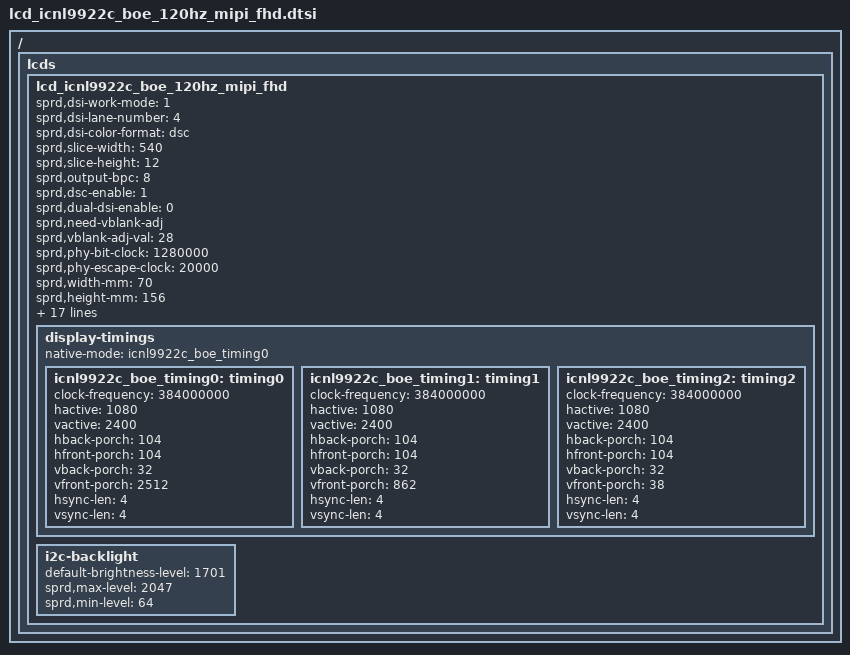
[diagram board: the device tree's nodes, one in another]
/ {
	fragment {
		target-path = "/";
		__overlay__ {
			lcds {
				lcd_icnl9922c_boe_120hz_mipi_fhd: lcd_icnl9922c_boe_120hz_mipi_fhd {

					sprd,dsi-work-mode = <1>; /* video burst mode*/
					sprd,dsi-lane-number = <4>;
					sprd,dsi-color-format = "dsc";
					sprd,slice-width = <540>;
					sprd,slice-height = <12>;
					sprd,output-bpc = <8>;
					sprd,dsc-enable = <1>;
					sprd,dual-dsi-enable = <0>;
					sprd,need-vblank-adj;
					sprd,vblank-adj-val = <28>;

					sprd,phy-bit-clock = <1280000>;
					sprd,phy-escape-clock = <20000>;/* kHz */
					sprd,width-mm = <70>;
					sprd,height-mm = <156>;
					sprd,vrr-enabled;
					sprd,esd-check-enable = <1>;
					sprd,esd-check-mode = <1>;
					sprd,esd-check-period = <2000>;
					/*sprd,esd-check-register = <0xA>;*/
					/*sprd,esd-check-value = <0x9c>;*/

					sprd,reset-on-sequence = <1 15>, <0 5>, <1 15>;
					sprd,reset-off-sequence = <1 10>;
					/*ontim,tp-reset-flag;*/
					sprd,need-execute-shutdown;
					ontim,qrcode-read-flag;
					sprd,qrcode-reg = <0x95 23>;
					sprd,qrcode-read-command = [
						39 00 00 04 F0 99 22 0C
						];

					sprd,initial-command = [
						39 00 00 04 F0 99 22 0C
						39 00 00 13 C1 00 00 20 26 26 04 68 68 04 60 19 22 50 01 12 07 5F FF
						39 00 00 06 C2 00 05 01 10 80
						39 00 00 0E B8 03 01 01 81 00 80 00 00 00 00 1F 00 20
						15 00 00 02 BA 01
						39 00 00 06 D0 0C 23 18 00 00
						39 00 00 03 35 00 00
						39 02 00 03 55 03 00
						39 00 00 03 51 07 FF
						39 00 00 14 E0 0C 00 B0 0C 00 15 7C 29 04 21 01 00 00 00 00 2E 17 0C 98
						39 00 00 20 E1 0F 1F 2F 3F 4F 5F 6F 7F 90 A0 B0 C0 D0 E0 E8 EC ED EF F1 F8 F8 F8 F9 FB FB FC FD FE FF FF FF
						39 00 00 21 E2 36 24 37 4B 38 72 39 99 3D 00 3C 0F 3B C2 3B A5 3C 28 3C ED 3D B1 3E 76 3F 3A 3F FF 3F FF 3F FF
						39 00 00 04 F0 00 00 00
						39 00 00 03 53 2C 00
						39 64 00 03 11 00 00
						39 0A 00 03 29 00 00
						39 01 00 03 AC 05 00
						];

					sprd,sleep-in-command = [
						39 00 00 04 F0 99 22 0C
						39 00 00 09 BB 01 02 03 0A 04 13 14 12
						39 00 00 04 F0 00 00 00
						39 00 00 03 AC 0A 00
						39 14 00 03 28 00 00
						39 78 00 03 10 00 00
						];
					sprd,sleep-out-command = [
						39 00 00 04 F0 99 22 0C
						39 00 00 13 C1 00 00 20 26 26 04 68 68 04 60 19 22 50 01 12 07 5F FF
						39 00 00 06 C2 00 05 01 10 80
						39 00 00 0E B8 03 01 01 81 00 80 00 00 00 00 1F 00 20
						15 00 00 02 BA 01
						39 00 00 06 D0 0C 23 18 00 00
						39 00 00 14 E0 0C 00 B0 0C 00 15 7C 29 04 81 1F 00 00 00 00 2E 17 0C 98
						39 00 00 20 E1 0F 1F 2F 3F 4F 5F 6F 7F 90 A0 B0 C0 D0 E0 E8 EC ED EF F1 F8 F8 F8 F9 FB FB FC FD FE FF FF FF
						39 00 00 21 E2 36 24 37 4B 38 72 39 99 3D 00 3C 0F 3B C2 3B A5 3C 28 3C ED 3D B1 3E 76 3F 3A 3F FF 3F FF 3F FF
						39 00 00 04 F0 00 00 00
						39 00 00 03 35 00 00
						39 02 00 03 55 03 00
						39 00 00 03 51 07 FF
						39 00 00 03 53 2C 00
						39 64 00 03 11 00 00
						39 0A 00 03 29 00 00
						39 01 00 03 AC 05 00
						];

					display-timings {
						native-mode = <&icnl9922c_boe_timing0>;
						icnl9922c_boe_timing0: timing0 {
							clock-frequency = <384000000>;
							hactive = <1080>;
							vactive = <2400>;
							hback-porch = <104>;
							hfront-porch = <104>;
							vback-porch = <32>;
							vfront-porch = <2512>;
							hsync-len = <4>;
							vsync-len = <4>;
						};
						icnl9922c_boe_timing1: timing1 {
							clock-frequency = <384000000>;
							hactive = <1080>;
							vactive = <2400>;
							hback-porch = <104>;
							hfront-porch = <104>;
							vback-porch = <32>;
							vfront-porch = <862>;
							hsync-len = <4>;
							vsync-len = <4>;
						};
						icnl9922c_boe_timing2: timing2 {
							clock-frequency = <384000000>;
							hactive = <1080>;
							vactive = <2400>;
							hback-porch = <104>;
							hfront-porch = <104>;
							vback-porch = <32>;
							vfront-porch = <38>;
							hsync-len = <4>;
							vsync-len = <4>;
						};
					};
					i2c-backlight {
						default-brightness-level = <1701>;
						sprd,max-level = <2047>;
						sprd,min-level = <64>;
					};
				};
			};
		};
	};
};
